# SC32F10T_10G register map
File version: 1.0
CPU: CM0+ r0p1, little endian, MPU, no FPU, 4 interrupt priority bits
Registers are 32-bit, read-write, reset 0x0 unless marked. A register's access mark holds for its fields unless they carry their own. Offsets are from the block's base; [hi:lo] are bit positions; 'fields as' and 'values as' point back to an identical list.

## TIM4
Base 0x40021100
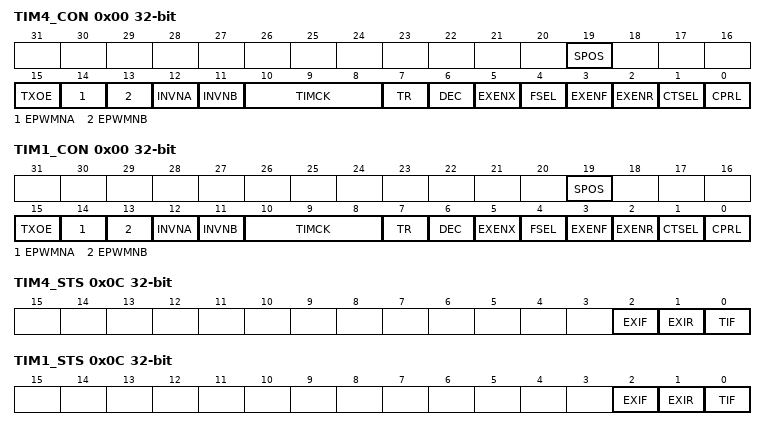
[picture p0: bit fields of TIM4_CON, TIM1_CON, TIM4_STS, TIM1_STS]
0x00 TIM4_CON — 定时器控制寄存器
  [19] SPOS — TIM2管脚映射控制位@ TIM2_CON 信号SPOS值T2CAP/T2SPOS=0PA10SPOS=1PA12TIM3管脚映射控制位@ TIM3_CON 信号SPOS值T3CAP/T3SPOS=0PA0SPOS=1PA13TIM7管脚映射控制位@ TIM7
  [15] TXOE — Tn引脚信号方向控制位0：Tn作为时钟输入口或I/O 端口1：Tn用于可编程时钟输出
  [14] EPWMNA — Tn_PWMA所在管脚 PWM波形输出使能位0：关闭1：使能
  [13] EPWMNB — TnEX_PWMB所在管脚 PWM波形输出使能位0：关闭1：使能
  [12] INVNA — TPWMnA波形输出反向控制位0：正常1：波形输出反向
  [11] INVNB — TPWMnB波形输出反向控制位0：正常1：波形输出反向
  [10:8] TIMCK — TIM时钟频率档位控制位000：fTIM/1001：fTIM/2010：fTIM/4011：fTIM/8100：fTIM/16101：fTIM/32110：fTIM/64111：fTIM/128fTIM对应的时钟可能为fPCLK 或Tn输入
  [7] TR — TIMn开始/停止控制位，n=0~7 0：停止TIMn / TPWMn计数器 1：开始TIMn / TPWMn计数器
  [6] DEC — 递增/递减方向控制位 0：TIMn为递增的定时/计数器 1：TIMn作为递增/递减的定时/计数器，TnEX用来选择计数方向
  [5] EXENX — TnEX设置位，n=0该位在不同模式下作用不同：重载模式：（CPRL = 0） 该位用于控制TnEX引脚上的外部事件输入(下降沿)，用作重载允许/禁止控制： 0：忽略TnEX引脚上的事件 1：检测到TnEX引脚上一个下降沿，产生一个重载捕获模式：（CPRL = 1） 该位用作TnEX下降沿信号捕获选通位： 0：忽略TnEX引脚上的事件 1：当FSEL = 1，检测到TnEX引脚上一个下降沿，产生一
  [4] FSEL — 下降沿信号选择位该位仅在捕获模式（CPRL=1)下有效 0：检测到Tn引脚上一个下降沿，产生一个捕获。忽略TnEX引脚上的事件 1：检测到TnEX引脚上一个下降沿，产生一个捕获。忽略Tn引脚上的事件
  [3] EXENF — 下降沿信号捕获使能位:0：忽略Tn引脚上的事件 1：检测到Tn引脚上一个下降沿，产生一个捕获，EXIF被置起，TnCNT寄存器的值捕获到寄存器FCAP里
  [2] EXENR — Tn引脚上的上升沿信号捕获使能位 0：忽略Tn引脚上的事件 1：检测到Tn引脚上一个上升沿，产生一个捕获，EXIR被置起，TnCNT寄存器的值捕获到寄存器RCAP里
  [1] CTSEL — 定时器/计数器选定位 0：定时器方式 1：计数器方式
  [0] CPRL — 捕获/重载方式设置位 0：重载功能 1：捕获功能
0x00 TIM1_CON — 定时器控制寄存器
  fields as TIM4_CON
0x04 TIM4_CNT — 定时器计数值寄存器
  [15:0] CNT — TIMn计数值
0x04 TIM1_CNT — 定时器计数值寄存器
  [15:0] CNT — TIMn计数值
0x08 TIM4_RLD — 定时器重载寄存器
  [15:0] RLD — 定时器溢出或在外部输入TnEX上的下降沿都能触发一个16位重载。产生重载时，定时器自动将用户软件写好的RLD[15:0]值装入TnCNT寄存器。
0x08 TIM1_RLD — 定时器重载寄存器
  fields as TIM4_RLD
0x0C TIM4_STS — 定时标志位寄存器
  [2] EXIF — 外部事件输入下降沿被检测到的标志位该位由硬件置1，通过软件写1清0。 0：无外部事件输入 1：检测到外部输入(如果EXENF = 1，由硬件设1) 注意：捕获模式下，该位软件清0之前不允许更新TnFCAP值
  [1] EXIR — Tn引脚外部事件输入上升沿被检测到的标志位该位由硬件置1，通过软件写1清0。 0：无外部事件输入 1：检测到外部输入(如果EXENR = 1，由硬件设1) 注意：捕获模式下，该位软件清0之前不允许更新TnRCAP值
  [0] TIF — 定时器溢出标志位该位由硬件置1，通过软件写1清0。 0：无溢出(必须由软件清0) 1：溢出(如果RCLK = 0和TCLK = 0，由硬件设1)
0x0C TIM1_STS — 定时标志位寄存器
  fields as TIM4_STS
0x10 TIM4_PDTA — TnPWMA占空比设定寄存器（@CPRL = 0）
  [15:0] PDT — TPWMnA 占空比寄存器，n=1~7TPWMnA的波形的高电平宽度是PDT[15:0]个TIM时钟
0x10 TIM1_PDTA — TnPWMA占空比设定寄存器（@CPRL = 0）
  [15:0] PDT — TPWMnA 占空比寄存器，n=1~7TPWMnA的波形的高电平宽度是PDT[15:0]个TIM时钟
0x14 TIM4_FCAP — 下降沿数据捕获寄存器（@CPRL = 1）
  [15:0] FCAP — TIMn的PWM捕获模式下，当下降沿捕获条件发生，CNT计数器值将被保存到该寄存器。
0x14 TIM1_FCAP — 下降沿数据捕获寄存器（@CPRL = 1）
  [15:0] FCAP — TIMn的PWM捕获模式下，当下降沿捕获条件发生，CNT计数器值将被保存到该寄存器。
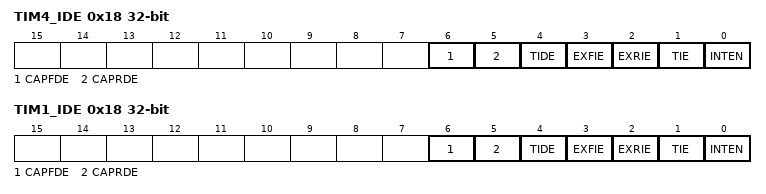
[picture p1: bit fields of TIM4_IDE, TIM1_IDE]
0x18 TIM4_IDE — TIMn的中断使能及DMA控制寄存器
  [6] CAPFDE — 下降沿捕获事件触发DMA请求使能位 0：下降沿捕获事件禁止产生DMA请求 1：产生新的下降沿捕获时，触发DMA请求，DMA搬运FCAP寄存器的值
  [5] CAPRDE — 上升沿捕获事件触发DMA请求使能位 0：上升沿捕获事件禁止产生DMA请求 1：产生新的下降沿捕获时，触发DMA请求，DMA搬运RCAP寄存器的值
  [4] TIDE — 定时器溢出事件触发DMA请求使能位 0：定时器溢出禁止产生DMA请求 1：定时器溢出允许产生DMA请求
  [3] EXFIE — 外部事件输入下降沿中断开关 0：禁止下降沿中断 1：使能下降沿中断
  [2] EXRIE — 外部事件输入上升沿中断开关 0：禁止上升沿中断 1：使能上升沿中断
  [1] TIE — 定时器溢出中断开关 0：禁止溢出中断 1：使能溢出中断
  [0] INTEN — 中断请求 CPU的使能控制位0：禁止中断请求1：使能中断请求
0x18 TIM1_IDE — TIMn的中断使能及DMA控制寄存器
  fields as TIM4_IDE

## TIM5
Base 0x40021140
Registers as TIM4 (with TIM4 read as TIM5).

## TIM6
Base 0x40021180
Registers as TIM4 (with TIM4 read as TIM6).

## TIM7
Base 0x400211C0
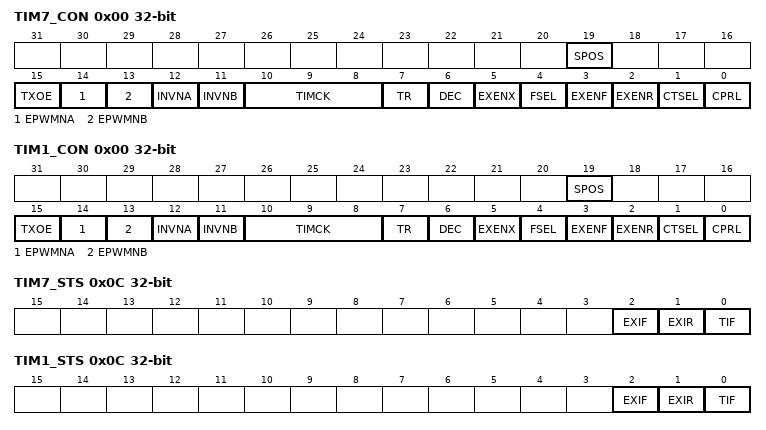
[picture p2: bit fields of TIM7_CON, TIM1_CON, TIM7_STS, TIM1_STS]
0x00 TIM7_CON — 定时器控制寄存器
  [19] SPOS — TIM2管脚映射控制位@ TIM2_CON 信号SPOS值T2CAP/T2SPOS=0PA10SPOS=1PA12TIM3管脚映射控制位@ TIM3_CON 信号SPOS值T3CAP/T3SPOS=0PA0SPOS=1PA13TIM7管脚映射控制位@ TIM7
  [15] TXOE — Tn引脚信号方向控制位0：Tn作为时钟输入口或I/O 端口1：Tn用于可编程时钟输出
  [14] EPWMNA — Tn_PWMA所在管脚 PWM波形输出使能位0：关闭1：使能
  [13] EPWMNB — TnEX_PWMB所在管脚 PWM波形输出使能位0：关闭1：使能
  [12] INVNA — TPWMnA波形输出反向控制位0：正常1：波形输出反向
  [11] INVNB — TPWMnB波形输出反向控制位0：正常1：波形输出反向
  [10:8] TIMCK — TIM时钟频率档位控制位000：fTIM/1001：fTIM/2010：fTIM/4011：fTIM/8100：fTIM/16101：fTIM/32110：fTIM/64111：fTIM/128fTIM对应的时钟可能为fPCLK 或Tn输入
  [7] TR — TIMn开始/停止控制位，n=0~7 0：停止TIMn / TPWMn计数器 1：开始TIMn / TPWMn计数器
  [6] DEC — 递增/递减方向控制位 0：TIMn为递增的定时/计数器 1：TIMn作为递增/递减的定时/计数器，TnEX用来选择计数方向
  [5] EXENX — TnEX设置位，n=0该位在不同模式下作用不同：重载模式：（CPRL = 0） 该位用于控制TnEX引脚上的外部事件输入(下降沿)，用作重载允许/禁止控制： 0：忽略TnEX引脚上的事件 1：检测到TnEX引脚上一个下降沿，产生一个重载捕获模式：（CPRL = 1） 该位用作TnEX下降沿信号捕获选通位： 0：忽略TnEX引脚上的事件 1：当FSEL = 1，检测到TnEX引脚上一个下降沿，产生一
  [4] FSEL — 下降沿信号选择位该位仅在捕获模式（CPRL=1)下有效 0：检测到Tn引脚上一个下降沿，产生一个捕获。忽略TnEX引脚上的事件 1：检测到TnEX引脚上一个下降沿，产生一个捕获。忽略Tn引脚上的事件
  [3] EXENF — 下降沿信号捕获使能位:0：忽略Tn引脚上的事件 1：检测到Tn引脚上一个下降沿，产生一个捕获，EXIF被置起，TnCNT寄存器的值捕获到寄存器FCAP里
  [2] EXENR — Tn引脚上的上升沿信号捕获使能位 0：忽略Tn引脚上的事件 1：检测到Tn引脚上一个上升沿，产生一个捕获，EXIR被置起，TnCNT寄存器的值捕获到寄存器RCAP里
  [1] CTSEL — 定时器/计数器选定位 0：定时器方式 1：计数器方式
  [0] CPRL — 捕获/重载方式设置位 0：重载功能 1：捕获功能
0x00 TIM1_CON — 定时器控制寄存器
  fields as TIM7_CON
0x04 TIM7_CNT — 定时器计数值寄存器
  [15:0] CNT — TIMn计数值
0x04 TIM1_CNT — 定时器计数值寄存器
  [15:0] CNT — TIMn计数值
0x08 TIM7_RLD — 定时器重载寄存器
  [15:0] RLD — 定时器溢出或在外部输入TnEX上的下降沿都能触发一个16位重载。产生重载时，定时器自动将用户软件写好的RLD[15:0]值装入TnCNT寄存器。
0x08 TIM1_RLD — 定时器重载寄存器
  fields as TIM7_RLD
0x0C TIM7_STS — 定时标志位寄存器
  [2] EXIF — 外部事件输入下降沿被检测到的标志位该位由硬件置1，通过软件写1清0。 0：无外部事件输入 1：检测到外部输入(如果EXENF = 1，由硬件设1) 注意：捕获模式下，该位软件清0之前不允许更新TnFCAP值
  [1] EXIR — Tn引脚外部事件输入上升沿被检测到的标志位该位由硬件置1，通过软件写1清0。 0：无外部事件输入 1：检测到外部输入(如果EXENR = 1，由硬件设1) 注意：捕获模式下，该位软件清0之前不允许更新TnRCAP值
  [0] TIF — 定时器溢出标志位该位由硬件置1，通过软件写1清0。 0：无溢出(必须由软件清0) 1：溢出(如果RCLK = 0和TCLK = 0，由硬件设1)
0x0C TIM1_STS — 定时标志位寄存器
  fields as TIM7_STS
0x10 TIM7_PDTA — TnPWMA占空比设定寄存器（@CPRL = 0）
  [15:0] PDT — TPWMnA 占空比寄存器，n=1~7TPWMnA的波形的高电平宽度是PDT[15:0]个TIM时钟
0x10 TIM1_PDTA — TnPWMA占空比设定寄存器（@CPRL = 0）
  [15:0] PDT — TPWMnA 占空比寄存器，n=1~7TPWMnA的波形的高电平宽度是PDT[15:0]个TIM时钟
0x14 TIM7_FCAP — 下降沿数据捕获寄存器（@CPRL = 1）
  [15:0] FCAP — TIMn的PWM捕获模式下，当下降沿捕获条件发生，CNT计数器值将被保存到该寄存器。
0x14 TIM1_FCAP — 下降沿数据捕获寄存器（@CPRL = 1）
  [15:0] FCAP — TIMn的PWM捕获模式下，当下降沿捕获条件发生，CNT计数器值将被保存到该寄存器。
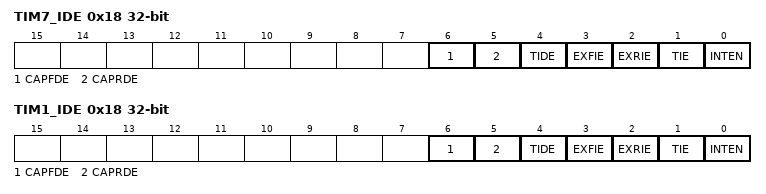
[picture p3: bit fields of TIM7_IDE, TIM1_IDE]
0x18 TIM7_IDE — TIMn的中断使能及DMA控制寄存器
  [6] CAPFDE — 下降沿捕获事件触发DMA请求使能位 0：下降沿捕获事件禁止产生DMA请求 1：产生新的下降沿捕获时，触发DMA请求，DMA搬运FCAP寄存器的值
  [5] CAPRDE — 上升沿捕获事件触发DMA请求使能位 0：上升沿捕获事件禁止产生DMA请求 1：产生新的下降沿捕获时，触发DMA请求，DMA搬运RCAP寄存器的值
  [4] TIDE — 定时器溢出事件触发DMA请求使能位 0：定时器溢出禁止产生DMA请求 1：定时器溢出允许产生DMA请求
  [3] EXFIE — 外部事件输入下降沿中断开关 0：禁止下降沿中断 1：使能下降沿中断
  [2] EXRIE — 外部事件输入上升沿中断开关 0：禁止上升沿中断 1：使能上升沿中断
  [1] TIE — 定时器溢出中断开关 0：禁止溢出中断 1：使能溢出中断
  [0] INTEN — 中断请求 CPU的使能控制位0：禁止中断请求1：使能中断请求
0x18 TIM1_IDE — TIMn的中断使能及DMA控制寄存器
  fields as TIM7_IDE

## DMA0
Base 0x40010800
0x00 DMA0_SADR — DMA 源地址缓存寄存器
  [31:0] SADR — DMA传输源地址缓存读取：当通道打开时，读到的是内部的源地址工作寄存器；当通道禁止时，读到的是表面上的源地址缓存寄存器。更新：每搬运完一次，源地址工作寄存器会根据SAINC[1:0]设置自动变化，其变化的宽度根据TXWIDTH[1:0]决定。循环模式下(SAINC == 11)，源地址缓存寄存器会重载至源地址工作寄存器。写入：写源地址缓存寄存器的条件：CHEN=0，或CHEN=1，但DMA通道已传
0x04 DMA0_DADR — DMA 目标地址缓存寄存器
  [31:0] DADR — DMA传输目标地址缓存读取：当通道打开时，读到的是内部的目标地址工作寄存器；当通道禁止时，读到的是表面上的目标地址缓存寄存器。更新：每搬运完一次，目标地址工作寄存器会根据DAINC[1:0]设置自动变化，其变化的宽度根据TXWIDTH[1:0]决定。循环模式下(SAINC == 11)，目标地址缓存寄存器会重载至目标地址工作寄存器。写入：写目标地址缓存寄存器的条件：CHEN=0，或CHEN=1，但
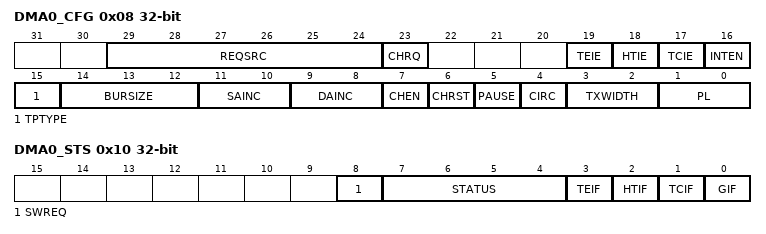
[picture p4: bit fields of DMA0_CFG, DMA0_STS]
0x08 DMA0_CFG — DMA 控制/配置寄存器
  [29:24] REQSRC — DMA通道请求源选择位0：禁用当前DMA通道的外设请求选择以下配置值，当前DMA通道的外设请求源将配合设置项中的外设DMA请求使能开关产生：2：UART0_IDE->TXDMAEN3：UART0_IDE->RXDMAEN4：UART1_IDE->TXDMAEN5：UART1_IDE->RXDMAEN12：SPI0_IDE->TXDMAEN13：SPI0_IDE->RXDMAEN14：SPI1_ID
  [23] CHRQ — DMA通道的DMA请求使能位0：禁止，当前DMA通道禁止作为其它DMA通道的请求源1：使能，当前DMA通道可作为其它DMA通道的请求源，即当前DMA通道和其它外设一样，可产生DMA请求。该位使能后，可以实现DMA请求DMA，例如：CHRQ =1，DMA通道n完成数据搬运后，向DMA通道m产生一个DMA请求，通道m响应请求，将预先配置好的参数表更新至通道n的寄存器，从而实现通道n的参数自动更新。
  [19] TEIE — DMA 传输错误中断使能位0：DMA 传输错误中断除能1：DMA 传输错误中断使能
  [18] HTIE — DMA 传输一半中断使能位0：DMA 传输一半中断除能1：DMA 传输一半中断使能
  [17] TCIE — DMA 传输完成中断使能位0：DMA 传输完成中断除能1：DMA 传输完成中断使能
  [16] INTEN — 中断请求 CPU的使能控制位0：禁止中断请求1：使能中断请求
  [15] TPTYPE — DMA通道传输类型选择位0：单次传输1：批量传输。批量传输模式下，DMA控制器搬移DMACNT个数据仅需一次请求，通道响应该请求后，数据将以Burst方式进行传输，即以BURSIZE为单位进行数据搬运直到DMACNT递减为0，一次批量传输模式下的数据处理才算完成。
  [14:12] BURSIZE — 批量传输时，基于 Burst 传输方式下的定义，Burst 大小可选择：000：128001：64010：32011：16100：8101：4110：2111：1
  [11:10] SAINC — DMA通道传输源地址增减模式设置位00: 无增量(固定地址模式)01: 增量模式10: 减量模式11: 递增循环模式 (见DMA传输源地址缓存寄存器)SAINC[1:0]的值可以任意修改，在通道禁止时立即生效；在通道使能时，修改值在循环模式重装载时生效
  [9:8] DAINC — DMA 传输目标地址增减模式设置位00: 无增量(固定地址模式)01: 增量模式10: 减量模式11: 递增循环模式 (见DMA传输目标地址缓存寄存器)DAINC[1:0]的值可以任意修改，在通道禁止时立即生效；在通道使能时，修改值在循环模式重装载时生效
  [7] CHEN — DMA通道使能位0： DMA通道禁止1： DMA通道使能
  [6] CHRST — DMA通道复位控制位，该位用于控制DMA通道复位。0：无效1：当前DMA通道复位。此时，当前DMA通道的CHEN被除能，中断标志为被清除，其他寄存器的值保持不变
  [5] PAUSE — DMA通道传输暂停控制位0：无效1：当前DMA通道暂停。此时，当前DMA通道的CHEN被除能，状态机在完成当前读写周期后回到 state=1，内部寄存器的值处于保持状态(源/目的地址，计数器)，当再次使能当前DMA通道的CHEN时，当前DMA通道的会继续上一次的传输；PAUSE会被写CHEN的动作清0
  [4] CIRC — DMA通道循环模式使能位0：通道未处于循环模式，在达到设定的待传输数据数目时，该通道的DMACNT会保持为零；1：通道处于循环模式，在传输完成后该通道的DMACNT会自动重新装载之前设定的值。循环模式可用于处理循环缓冲区和连续数据流（例如ADC扫描模式）。在循环模式传输过程中，待传输数据的数目将自动重新装载为在通道配置阶段设置的初始值，并继续响应 DMA 请求。为停止循环传输，软件需要在禁止 DM
  [3:2] TXWIDTH — DMA通道传输宽度选择位选择当前DMA通道的源地址及目标地址每次传输的数据宽度：00：8bit01：16bit10：32bit11：32bitTXWIDTH[1:0] 的值可以任意修改，在通道禁止时，立即生效；在通道打开时，修改值在循环模式重装载时生效。
  [1:0] PL — DMA通道优先级设置位 在 DMA 已经有通道在工作，且其它通道也接收到请求正挂起，当正在工作的通道结束后将启动优先级仲裁。00：低01：中10：高11：非常高注意：同等优先级配置，通道号越小优先级越高。
0x0C DMA0_CNT — DMA 计数器缓存寄存器
  [31:0] DMACNT — DMA通道计数器缓存寄存器写入：DMACNT的值等于当前DMA通道的剩余传输次数；每个DMA通道内部都有一个“工作计数器”，该计数器会在每次搬运后以为TXWIDTH 为单位递减：当CIRC=0（DMA通道处于非循环模式）时，“工作计数器”递减到0后，将不再接受任何 DMA 请求。当CIRC=1（DMA通道处于循环模式）时，“工作计数器”递减到0后，会将DMACNT的值重载到“工作计数器”内，等待下
0x10 DMA0_STS — DMA 状态寄存器
  [8] SWREQ — DMA通道的软件请求触发位该位写1后，当前DMA通道会一直挂起软件请求，直到当前DMA通道响应，并将该位自动硬件清0。
  [7:4] STATUS — DMA通道状态位0000：空闲。0001：写入源地址0010：读取源地址数据，并写入目的地址0011：写入目的地址数据0100：保留0101：挂起等待中(有通道在忙，其他通道请求挂起)0110：暂停等待中(批量传输模式时PAUSE写1后)0111：burst传输中1000：burst传输停止：PAUSE使能、DMACNT计数到0，或bursize计数到0均会进入此状态
  [3] TEIF — DMA 传输错误中断标志位当DMA读写到未定义的地址时，TEIF会被硬件置1。该位写1清零。
  [2] HTIF — DMA 传输一半中断标志位当DMACNT的计数值计数到DMACNT/2时，HTIF会被硬件置1。该位写1清零。
  [1] TCIF — DMA 传输完成中断标志位当DMACNT的计数值计到0时，TCIF会被硬件置1。该位写1清零。
  [0] GIF — DMA通道全局中断标志位0：当前DMA通道无中断产生1：当前DMA通道产生中断：传输错误、传输到一半或传输完成
